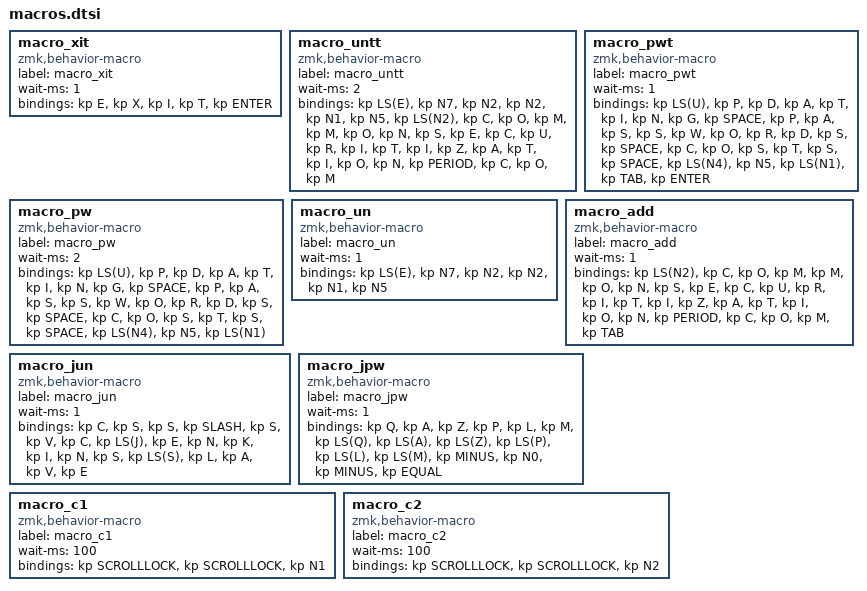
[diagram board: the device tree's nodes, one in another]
macro_xit: macro_xit{
compatible = "zmk,behavior-macro";
label = "macro_xit";
#binding-cells = <0>;
wait-ms=<1>;
bindings = <&kp E>, <&kp X>, <&kp I>, <&kp T>, <&kp ENTER>;
};
macro_untt: macro_untt{
compatible = "zmk,behavior-macro";
label = "macro_untt";
#binding-cells = <0>;
wait-ms=<2>;
bindings = <&kp LS(E)>, <&kp N7>, <&kp N2>, <&kp N2>, <&kp N1>, <&kp N5>, <&kp LS(N2)>, <&kp C>, <&kp O>, <&kp M>, <&kp M>, <&kp O>, <&kp N>, <&kp S>, <&kp E>, <&kp C>, <&kp U>, <&kp R>, <&kp I>, <&kp T>, <&kp I>, <&kp Z>, <&kp A>, <&kp T>, <&kp I>, <&kp O>, <&kp N>, <&kp PERIOD>, <&kp C>, <&kp O>, <&kp M>;
};
macro_pwt: macro_pwt{
compatible = "zmk,behavior-macro";
label = "macro_pwt";
#binding-cells = <0>;
wait-ms=<1>;
bindings = <&kp LS(U)>, <&kp P>, <&kp D>, <&kp A>, <&kp T>, <&kp I>, <&kp N>, <&kp G>, <&kp SPACE>, <&kp P>, <&kp A>, <&kp S>, <&kp S>, <&kp W>, <&kp O>, <&kp R>, <&kp D>, <&kp S>, <&kp SPACE>, <&kp C>, <&kp O>, <&kp S>, <&kp T>, <&kp S>, <&kp SPACE>, <&kp LS(N4)>, <&kp N5>, <&kp LS(N1)>, <&kp TAB>, <&kp ENTER>;
};
macro_pw: macro_pw{
compatible = "zmk,behavior-macro";
label = "macro_pw";
#binding-cells = <0>;
wait-ms=<2>;
bindings = <&kp LS(U)>, <&kp P>, <&kp D>, <&kp A>, <&kp T>, <&kp I>, <&kp N>, <&kp G>, <&kp SPACE>, <&kp P>, <&kp A>, <&kp S>, <&kp S>, <&kp W>, <&kp O>, <&kp R>, <&kp D>, <&kp S>, <&kp SPACE>, <&kp C>, <&kp O>, <&kp S>, <&kp T>, <&kp S>, <&kp SPACE>, <&kp LS(N4)>, <&kp N5>, <&kp LS(N1)>;
};
macro_un: macro_un{
compatible = "zmk,behavior-macro";
label = "macro_un";
#binding-cells = <0>;
wait-ms=<1>;
bindings = <&kp LS(E)>, <&kp N7>, <&kp N2>, <&kp N2>, <&kp N1>, <&kp N5>;
};
macro_add: macro_add{
compatible = "zmk,behavior-macro";
label = "macro_add";
#binding-cells = <0>;
wait-ms=<1>;
bindings = <&kp LS(N2)>, <&kp C>, <&kp O>, <&kp M>, <&kp M>, <&kp O>, <&kp N>, <&kp S>, <&kp E>, <&kp C>, <&kp U>, <&kp R>, <&kp I>, <&kp T>, <&kp I>, <&kp Z>, <&kp A>, <&kp T>, <&kp I>, <&kp O>, <&kp N>, <&kp PERIOD>, <&kp C>, <&kp O>, <&kp M>, <&kp TAB>;
};
macro_jun: macro_jun{
compatible = "zmk,behavior-macro";
label = "macro_jun";
#binding-cells = <0>;
wait-ms=<1>;
bindings = <&kp C>, <&kp S>, <&kp S>, <&kp SLASH>, <&kp S>, <&kp V>, <&kp C>, <&kp LS(J)>, <&kp E>, <&kp N>, <&kp K>, <&kp I>, <&kp N>, <&kp S>, <&kp LS(S)>, <&kp L>, <&kp A>, <&kp V>, <&kp E>;
};
macro_jpw: macro_jpw{
compatible = "zmk,behavior-macro";
label = "macro_jpw";
#binding-cells = <0>;
wait-ms=<1>;
bindings = <&kp Q>, <&kp A>, <&kp Z>, <&kp P>, <&kp L>, <&kp M>, <&kp LS(Q)>, <&kp LS(A)>, <&kp LS(Z)>, <&kp LS(P)>, <&kp LS(L)>, <&kp LS(M)>, <&kp MINUS>, <&kp N0>, <&kp MINUS>, <&kp EQUAL>;
};
macro_c1: macro_c1{
compatible = "zmk,behavior-macro";
label = "macro_c1";
#binding-cells = <0>;
wait-ms=<100>;
bindings = <&kp SCROLLLOCK>, <&kp SCROLLLOCK>, <&kp N1>;
};
macro_c2: macro_c2{
compatible = "zmk,behavior-macro";
label = "macro_c2";
#binding-cells = <0>;
wait-ms=<100>;
bindings = <&kp SCROLLLOCK>, <&kp SCROLLLOCK>, <&kp N2>;
};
